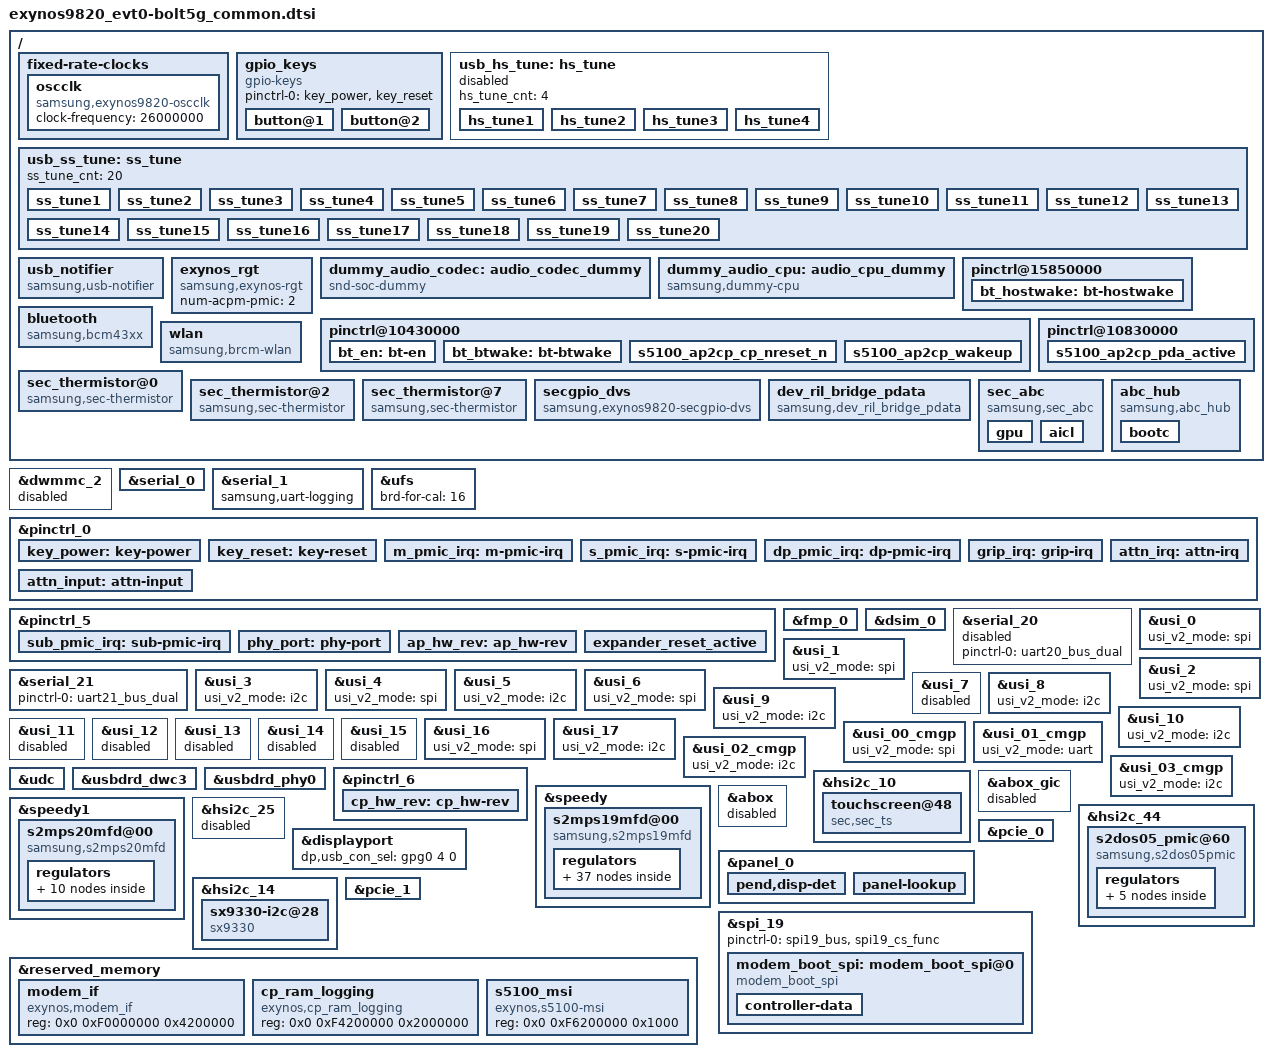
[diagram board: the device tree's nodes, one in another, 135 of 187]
/*
 * SAMSUNG EXYNOS9820 board device tree source
 *
 * Copyright (c) 2018 Samsung Electronics Co., Ltd.
 *		http://www.samsung.com
 *
 * This program is free software; you can redistribute it and/or modify
 * it under the terms of the GNU General Public License version 2 as
 * published by the Free Software Foundation.
*/
#include "modem-s5100-sipc-pdata.dtsi"

/ {

	fragment@model {
		target-path = "/";
		__overlay__ {
			#address-cells = <2>;
			#size-cells = <1>;

			fixed-rate-clocks {
				oscclk {
					compatible = "samsung,exynos9820-oscclk";
					clock-frequency = <26000000>;
				};
			};

			gpio_keys {
				status = "okay";
				compatible = "gpio-keys";
				pinctrl-names = "default";
				pinctrl-0 = <&key_power &key_reset>;
				button@1 {
					label = "gpio-keys: KEY_POWER";
					linux,code = <116>;
					gpios = <&gpa2 4 0xf>;
					gpio-key,wakeup = <1>;
				};
				button@2 {
					label = "gpio-keys: KEY_RESET";
					linux,code = <461>;
					gpios = <&gpa1 1 0xf>;
					gpio-key,wakeup = <1>;
				};
			};

			usb_hs_tune:hs_tune {
				status = "disabled";
				hs_tune_cnt = <4>;
				/* value = <device host> */
				hs_tune1 {
					tune_name = "tx_pre_emp";
					tune_value = <0x3 0x3>;
				};

				hs_tune2 {
					tune_name = "tx_vref";
					tune_value = <0xc 0xc>;
				};

				hs_tune3 {
					tune_name = "rx_sqrx";
					tune_value = <0x5 0x5>;
				};

				hs_tune4 {
					tune_name = "utmi_clk";
					tune_value = <0x1 0x1>;
				};
			};

			usb_ss_tune:ss_tune {
				status = "okay";
				ss_tune_cnt = <20>;
				/* value = <device host> */
				ss_tune1 {
					tune_name = "ssrx_sqhs_th";
					tune_value = <0x4 0x4>;
				};

				ss_tune2 {
					tune_name = "ssrx_lfps_th";
					tune_value = <0x2 0x2>;
				};

				ss_tune3 {
					tune_name = "ssrx_mf_eq_en";
					tune_value = <0x1 0x1>;
				};

				ss_tune4 {
					tune_name = "ssrx_mf_eq_ctrl_ss";
					tune_value = <0x6 0x6>;
				};

				ss_tune5 {
					tune_name = "ssrx_hf_eq_ctrl_ss";
					tune_value = <0xc 0xe>;
				};

				ss_tune6 {
					tune_name = "ssrx_mf_eq_ctrl_ssp";
					tune_value = <0x6 0x6>;
				};

				ss_tune7 {
					tune_name = "ssrx_hf_eq_ctrl_ssp";
					tune_value = <0xe 0xe>;
				};

				ss_tune8 {
					tune_name = "ssrx_dfe1_tap_ctrl";
					tune_value = <0x0 0x2>;
				};

				ss_tune9 {
					tune_name = "ssrx_dfe2_tap_ctrl";
					tune_value = <0x0 0x0>;
				};

				ss_tune10 {
					tune_name = "ssrx_dfe3_tap_ctrl";
					tune_value = <0x0 0x0>;
				};

				ss_tune11 {
					tune_name = "ssrx_dfe4_tap_ctrl";
					tune_value = <0x0 0x0>;
				};

				ss_tune12 {
					tune_name = "ssrx_dfe5_tap_ctrl";
					tune_value = <0x0 0x0>;
				};

				ss_tune13 {
					tune_name = "ssrx_term_cal";
					tune_value = <0xb 0xb>;
				};

				ss_tune14 {
					tune_name = "sstx_amp";
					tune_value = <0xb 0xb>;
				};

				ss_tune15 {
					tune_name = "sstx_deemp";
					tune_value = <0x5 0x5>;
				};

				ss_tune16 {
					tune_name = "sstx_pre_shoot";
					tune_value = <0x3 0x3>;
				};

				ss_tune17 {
					tune_name = "sstx_idrv_up";
					tune_value = <0x7 0x7>;
				};

				ss_tune18 {
					tune_name = "sstx_idrv_dn";
					tune_value = <0x0 0x0>;
				};

				ss_tune19 {
					tune_name = "sstx_up_term";
					tune_value = <0x3 0x3>;
				};

				ss_tune20 {
					tune_name = "sstx_dn_term";
					tune_value = <0x3 0x3>;
				};
			};

			usb_notifier {
				compatible = "samsung,usb-notifier";
				/*
				 * USB_LDOCONTROL_EXYNOS8895	1
				 * USB_LDOCONTROL_EXYNOS9810	2
				 * USB_LDOCONTROL_EXYNOS9820	3
				 */
				usb-ldocontrol = <3>;
				udc = <&udc>;
				disable_host_wakelock;
			};

			exynos_rgt {
				compatible = "samsung,exynos-rgt";
				num-acpm-pmic = <2>;
			};

			dummy_audio_codec: audio_codec_dummy {
				status = "okay";
				compatible = "snd-soc-dummy";
			};

			dummy_audio_cpu: audio_cpu_dummy {
				compatible = "samsung,dummy-cpu";
				status = "okay";
			};

			pinctrl@15850000 {
				bt_hostwake: bt-hostwake {
					samsung,pins = "gpa2-3";
					samsung,pin-function = <0>;
					samsung,pin-pud = <0>;
				};
			};

			pinctrl@10430000 {
				bt_en: bt-en {
					samsung,pins ="gpg0-6";
					samsung,pin-function = <1>;
					samsung,pin-pud = <1>;
					samsung,pin-con-pdn = <3>;
					samsung,pin-pud-pdn = <0>;
				};

				bt_btwake: bt-btwake {
					samsung,pins = "gpg2-0";
					samsung,pin-function = <1>;
					samsung,pin-pud = <0>;
					samsung,pin-con-pdn = <3>;
					samsung,pin-pud-pdn = <0>;
				};

				s5100_ap2cp_cp_nreset_n: s5100_ap2cp_cp_nreset_n {
					samsung,pins = "gpp3-1";
					samsung,pin-con-pdn = <3>;
				};

				s5100_ap2cp_wakeup: s5100_ap2cp_wakeup {
					samsung,pins = "gpg1-7";
					samsung,pin-con-pdn = <3>;
				};
			};

			pinctrl@10830000 {
				s5100_ap2cp_pda_active: s5100_ap2cp_pda_active {
					samsung,pins = "gph1-3";
					samsung,pin-con-pdn = <3>;
				};
			};

			bluetooth {
				compatible = "samsung,bcm43xx";
				gpios = <&gpg0 6 0    /*BT_EN*/
				&gpg2 0 0    /*BT_WAKE*/
				&gpa2 3 0xF    /*BT_HOST_WAKE*/ >;
				pinctrl-names = "default";
				pinctrl-0=<&bt_hostwake &bt_en &bt_btwake>;
				status = "okay";
			};
			
			wlan {
				compatible = "samsung,brcm-wlan";
				gpios = <&gpg0 5 0x1 /* WLAN_EN */
						&gpa0 7 0x1 /* WLAN HOST WAKE GPIO_0 */>;
				pinctrl-names = "default";
				pinctrl-0 = <&cfg_wlanen &wlan_host_wake>;
				status = "okay";
			};

			sec_thermistor@0 {
				compatible = "samsung,sec-thermistor";
				status = "okay";
				thermistor_name = "sec-ap-thermistor";
				id = <0>;

				adc_array = <275 324 380 450 528 619 729 856 1003 1161
					  1345 1545 1766 1980 2222 2457 2685 2901 3102 3279
					  3426 3551 3659>;
				temp_array = <900 850 800 750 700 650 600 550 500 450
					  400 350 300 250 200 150 100 50 0 (-50)
					  (-100) (-150) (-200)>;

				io-channels = <&exynos_adc 0>;
				io-channel-names = "adc-ap-temp";
				io-channel-ranges;
			};

			sec_thermistor@2 {
				compatible = "samsung,sec-thermistor";
				status = "okay";
				thermistor_name = "sec-wf-thermistor";
				id = <1>;

				adc_array = <275 324 380 450 528 619 729 856 1003 1161
					  1345 1545 1766 1980 2222 2457 2685 2901 3102 3279
					  3426 3551 3659>;
				temp_array = <900 850 800 750 700 650 600 550 500 450
					  400 350 300 250 200 150 100 50 0 (-50)
					  (-100) (-150) (-200)>;

				io-channels = <&exynos_adc 2>;
				io-channel-names = "adc-wf-temp";
				io-channel-ranges;
			};

			sec_thermistor@7 {
				compatible = "samsung,sec-thermistor";
				status = "okay";
				thermistor_name = "sec-pa-thermistor";
				id = <2>;

				adc_array = <327 347 367 388 410 433 456 482 507 534
					562 591 621 651 684 717 750 786 821 858
					896 935 975 1016 1057 1100 1143 1187 1231 1277
					1323 1369 1416 1463 1511 1559 1608 1657 1706 1755
					1804 1853 1902 1951 2000 2048 2096 2144 2192 2239
					2285 2332 2378 2421 2467 2510 2553 2596 2637 2678
					2719 2758 2797 2833 2872 2906 2942 2976 3011 3042
					3074 3106 3136 3165 3195 3222 3249 3277 3302 3327
					3352 3375 3397 3420 3441 3461 3482 3502 3520 3538
					3557 3573 3591 3607 3620 3636 3650 3666 3680 3691
					3705 3716 3730 3741 3752 3761 3773 3782 3793 3802
					3812>;

				temp_array =
					<(-200) (-190) (-180) (-170) (-160) (-150) (-140) (-130) (-120) (-110)
					(-100) (-90) (-80) (-70) (-60) (-50) (-40) (-30) (-20) (-10)
					0 10 20 30 40 50 60 70 80 90
					100 110 120 130 140 150 160 170 180 190
					200 210 220 230 240 250 260 270 280 290
					300 310 320 330 340 350 360 370 380 390
					400 410 420 430 440 450 460 470 480 490
					500 510 520 530 540 550 560 570 580 590
					600 610 620 630 640 650 660 670 680 690
					700 710 720 730 740 750 760 770 780 790
					800 810 820 830 840 850 860 870 880 890
					900>;

				io-channels = <&exynos_adc 7>;
				io-channel-names = "adc-pa-temp";
				io-channel-ranges;
			};

			secgpio_dvs {
				compatible = "samsung,exynos9820-secgpio-dvs";
				status = "okay";
			};

			dev_ril_bridge_pdata {
				compatible = "samsung,dev_ril_bridge_pdata";
				status = "okay";
			};

			sec_abc {
				compatible = "samsung,sec_abc";
				status = "okay";

				gpu {
					gpu,label="GPU fault";
					gpu,threshold_count=<20>;
					gpu,threshold_time=<1200>;
				};
				aicl {
					aicl,label="battery aicl";
					aicl,threshold_count=<5>;
					aicl,threshold_time=<300>;
				};
			};

			abc_hub {
				compatible = "samsung,abc_hub";
				status = "okay";

				bootc {
					bootc,time_spec_user = <100000>; /* user binary user build */
					bootc,time_spec_eng = <100000>; /* user binary eng build */
					bootc,time_spec_fac = <100000>; /* factory binary */
				};
			};
		}; /* end of __overlay__ */
	}; /* end of fragment */
}; /* end of root */

&dwmmc_2 {
	status = "disabled";
};


&serial_0 {
	status = "okay";
};

&serial_1 {
	samsung,uart-logging;
	status = "okay";
};

&ufs {
	/* board type for UFS CAL */
	brd-for-cal = /bits/ 8 <16>;  /* (1:SMDK, 16:UNIV) board */
};

&pinctrl_0 {
	key_power: key-power {
		samsung,pins = "gpa2-4";
		samsung,pin-function = <0xf>;
	};

	key_reset: key-reset {
		samsung,pins = "gpa1-1";
		samsung,pin-function = <0xf>;
		samsung,pin-pud = <0>;
		samsung,pin-drv = <0>;
	};

	m_pmic_irq: m-pmic-irq {
		samsung,pins = "gpa0-1";
		samsung,pin-pud = <3>;
		samsung,pin-drv = <3>;
	};

	s_pmic_irq: s-pmic-irq {
		samsung,pins = "gpa2-5";
		samsung,pin-pud = <3>;
		samsung,pin-drv = <3>;
	};

	dp_pmic_irq: dp-pmic-irq {
		samsung,pins = "gpa1-4";
		samsung,pin-function = <0>;
		samsung,pin-pud = <0>;
		samsung,pin-drv = <0>;
	};

	grip_irq: grip-irq {
		samsung,pins = "gpa3-0";
		samsung,pin-function = <0xf>;
		samsung,pin-pud = <0>;
		samsung,pin-drv = <3>;
	};
};

&pinctrl_5 {
	sub_pmic_irq: sub-pmic-irq {
		samsung,pins = "gpg2-1";
		samsung,pin-function = <0>;
		samsung,pin-pud = <0>;
		samsung,pin-drv = <0>;
	};
};

&fmp_0 {
	exynos,block-type = "sda";
	exynos,fips-block_offset = <5>;
};

&dsim_0 {
	lcd_info = <&s6e3ha8>;
	/* reset, power */
	gpios = <&gpa3 4 0x1>;
};

&serial_20 {
	pinctrl-names = "default";
	pinctrl-0 = <&uart20_bus_dual>;
	status = "disabled";
};

&serial_21 {
	pinctrl-names = "default";
	pinctrl-0 = <&uart21_bus_dual>;
	status = "okay";
};

&usi_0 {
	usi_v2_mode = "spi";
	status = "okay";
};

&usi_1 {
	usi_v2_mode = "spi";
	status = "okay";
};

&usi_2 {
	usi_v2_mode = "spi";
	status = "okay";
};

&usi_3 {
	usi_v2_mode = "i2c";
	status = "okay";
};

&usi_4 {
	usi_v2_mode = "spi";
	status = "okay";
};

&usi_5 {
	usi_v2_mode = "i2c";
	status = "okay";
};

&usi_6 {
	usi_v2_mode = "spi";
	status = "okay";
};

&usi_7 {
	status = "disabled";
};

&usi_8 {
	usi_v2_mode = "i2c";
	status = "okay";
};

&usi_9 {
	usi_v2_mode = "i2c";
	status = "okay";
};

&usi_10 {
	usi_v2_mode = "i2c";
	status = "okay";
};

&usi_11 {
	status = "disabled";
};

&usi_12 {
	status = "disabled";
};

&usi_13 {
	status = "disabled";
};

&usi_14 {
	status = "disabled";
};

&usi_15 {
	status = "disabled";
};

&usi_16 {
	usi_v2_mode = "spi";
	status = "okay";
};

&usi_17 {
	usi_v2_mode = "i2c";
	status = "okay";
};

&usi_00_cmgp {
	usi_v2_mode = "spi";
	status = "okay";
};

&usi_01_cmgp {
	usi_v2_mode = "uart";
	status = "okay";
};

&usi_02_cmgp {
	usi_v2_mode = "i2c";
	status = "okay";
};

&usi_03_cmgp {
	usi_v2_mode = "i2c";
	status = "okay";
};

&pinctrl_5 {
	phy_port: phy-port {
		samsung,pins = "gpg0-4";
		samsung,pin-function = <0x0>;
		samsung,pin-pud = <3>;
		samsung,pin-drv = <0>;
	};
};

&udc {
	status = "okay";
};

&usbdrd_dwc3 {
	dr_mode = "otg";
	maximum-speed = "super-speed-plus";
	snps,quirk-frame-length-adjustment = <0x20>;
	snps,u1u2_exitfail_quirk;
	/* ux_exit_in_px should be defined in MK, LT */
	snps,ux_exit_in_px_quirk;
	/* elastic_buf_mode_quirk should be defined in MK */
	snps,elastic_buf_mode_quirk;
	usb3-lpm-capable;
	snps,usb3_lpm_capable;
	snps,has-lpm-erratum;
	snps,lpm-nyet-threshold = <0>;
	/*
	 * dis-u2-freeclk-exists-quirk, dis_u2_susphy_quirk are alternative.
	 * One of them should be selected
	 */
	snps,dis-u2-freeclk-exists-quirk;
	/*snps,dis_u2_susphy_quirk;*/

	usb_audio_offloading = <1>;
	abox = <&abox>; /* Temporary block */
};

&usbdrd_phy0 {
	status = "okay";

	pinctrl-names = "default";
	pinctrl-0 = <&phy_port>; 
 	phy,gpio_phy_port = <&gpg0 4 0x0>;
	reverse_con_dir = <1>;
	hs_tune_param = <&usb_hs_tune>;
	ss_tune_param = <&usb_ss_tune>;
};

&pinctrl_6 {
	/* CP HW revision */
	cp_hw_rev: cp_hw-rev {
		samsung,pins = "gpg3-4", "gpg3-3", "gpg3-2", "gpg3-1";
		samsung,pin-function = <0>;
		samsung,pin-pud = <0>;
		samsung,pin-drv = <0>;
	};
};
&pinctrl_5 {
	/* AP HW revision */
	ap_hw_rev: ap_hw-rev {
		samsung,pins = "gpg1-5", "gpg1-4", "gpg1-3", "gpg1-2";
		samsung,pin-function = <0>;
		samsung,pin-pud = <0>;
		samsung,pin-drv = <0>;
	};
};

&pinctrl_0 {
	attn_irq: attn-irq {
		samsung,pins = "gpa1-0";
		samsung,pin-function = <0xf>;
		samsung,pin-pud = <0>;
		samsung,pin-drv = <0>;
	};

	attn_input: attn-input {
		samsung,pins = "gpa1-0";
		samsung,pin-function = <0>;
		samsung,pin-pud = <1>;
	};
};

&hsi2c_10 {
	#address-cells = <1>;
	#size-cells = <0>;
	status = "okay";
	samsung,reset-before-trans;
	samsung,stop-after-trans;	/* LSI IC ONLY */
	touchscreen@48 {
		compatible = "sec,sec_ts";
		reg = <0x48>;
		pinctrl-names = "on_state", "off_state";
		pinctrl-0 = <&attn_irq>;
		pinctrl-1 = <&attn_input>;
		sec,irq_gpio = <&gpa1 0 0>;
		sec,irq_type = <8200>;
		sec,max_coords = <4096 4096>;
//		sec,area-size = <133 266 341>; /* indicator: 24dp navigator:48dp edge:60px dpi=320 */
		sec,mis_cal_check = <1>;
		sec,regulator_dvdd = "tsp_io";
		sec,regulator_avdd = "tsp_avdd";
		sec,regulator_boot_on;
		sec,tclm_level = <1>;
		support_dex_mode;
		sec,factory_item_version = <2>;
		sec,bringup = <1>;
	};
};

&speedy {
	#address-cells = <1>;
	#size-cells = <0>;
	status = "okay";
	s2mps19mfd@00 {
		compatible = "samsung,s2mps19mfd";
		acpm-ipc-channel = <2>;
		acpm-speedy-channel = <0>;
		i2c-speedy-address;
		s2mps19,wakeup = "enabled";
		s2mps19,irq-gpio = <&gpa0 1 0>;
		reg = <0x00>;
		interrupts = <2 0 0>;
		interrupt-parent = <&gpa0>;
		pinctrl-names = "default";
		pinctrl-0 = <&m_pmic_irq &smpl_warn>;
		gpios = <&gpp3 4 0>;
		smpl_warn_en = <1>; /* 1 : enable , 0 : disable */
		/* range of smpl_warn_vth */
		/* 0x00 : 2.1V, 0x20 : 2.3V, 0x40 : 2.5V, 0x60 : 2.7V 0x80 : 2.9V */
		/* 0xA0 : 3.1V, 0xC0 : 3.3V, 0xE0 : 3.5V */
		smpl_warn_vth = <0xA0>;
		/* LowBat_Hys[4:3] 00(100mV), 01(200mV), 10(300mV), 11(400mV) */
		smpl_warn_hys = <0x00>;
		ocp_warn1_en = <0>; /* 1 : enable, 0 : disable */
		ocp_warn1_cnt = <0>; /* ocp warn reset timing control, 0 : 2 clock, 1 : 32 clock */
		ocp_warn1_dvs_mask = <0>; /* ocp warn mask when dvs, 0 : not masked, 1 : masked  */
		ocp_warn1_lv = <0x0>; /* step : -250mA */
		ocp_warn2_en = <0>; /* 1 : enable, 0 : disable */
		ocp_warn2_cnt = <0>; /* ocp warn reset timing control, 0 : 2 clock, 1 : 32 clock */
		ocp_warn2_dvs_mask = <0>; /* ocp warn mask when dvs, 0 : not masked, 1 : masked  */
		ocp_warn2_lv = <0x0>; /* step : -250mA */
		adc_mode = <1>; /* 0 : disable, 1 : current meter, 2 : power meter */
		adc_sync_mode = <2>; /* 1 : sync mode, 2 : async mode */
		/* RTC: wtsr/smpl */
		wtsr_en = "enabled"; /* enable */
		smpl_en = "enabled"; /* enable */
		wtsr_timer_val = <3>;	/* 1000ms */
		smpl_timer_val = <2>;	/* 300ms */
		sub_smpl_en = "enabled"; /* enable */
		check_jigon = <0>; /* do not check jigon */
		/* RTC: If it's first boot, reset rtc to 1/1/2017 12:00:00(Sun) */
		init_time,sec = <0>;
		init_time,min = <0>;
		init_time,hour = <12>;
		init_time,mday = <1>;
		init_time,mon = <0>;
		init_time,year = <117>;
		init_time,wday = <0>;

		regulators {
			buck1_reg: BUCK1M {
				regulator-name = "m_vdd_buck1";
				regulator-min-microvolt = <450000>;
				regulator-max-microvolt = <1100000>;
				regulator-always-on;
				regulator-ramp-delay = <6000>;
				regulator-initial-mode = <2>;
			};

			buck2_reg: BUCK2M {
				regulator-name = "m_vdd_buck2";
				regulator-min-microvolt = <450000>;
				regulator-max-microvolt = <1300000>;
				regulator-always-on;
				regulator-ramp-delay = <6000>;
				regulator-initial-mode = <2>;
			};

			buck3_reg: BUCK3M {
				regulator-name = "m_vdd_buck3";
				regulator-min-microvolt = <450000>;
				regulator-max-microvolt = <1300000>;
				regulator-always-on;
				regulator-ramp-delay = <6000>;
				regulator-initial-mode = <1>;
			};

			buck4_reg: BUCK4M {
				regulator-name = "m_vdd_buck4";
				regulator-min-microvolt = <450000>;
				regulator-max-microvolt = <1300000>;
				regulator-always-on;
				regulator-ramp-delay = <6000>;
				regulator-initial-mode = <1>;
			};

			buck5_reg: BUCK5M {
				regulator-name = "m_vdd_buck5";
				regulator-min-microvolt = <450000>;
				regulator-max-microvolt = <950000>;
				regulator-always-on;
				regulator-ramp-delay = <6000>;
				regulator-initial-mode = <2>;
			};

			buck6_reg: BUCK6M {
				regulator-name = "m_vdd_buck6";
				regulator-min-microvolt = <450000>;
				regulator-max-microvolt = <1100000>;
				regulator-always-on;
				regulator-ramp-delay = <6000>;
				regulator-initial-mode = <2>;
			};

			buck7_reg: BUCK7M {
				regulator-name = "m_vdd_buck7";
				regulator-min-microvolt = <450000>;
				regulator-max-microvolt = <1300000>;
				regulator-always-on;
				regulator-ramp-delay = <6000>;
				regulator-initial-mode = <2>;
			};

			buck8_reg: BUCK8M {
				regulator-name = "m_vdd_buck8";
				regulator-min-microvolt = <450000>;
				regulator-max-microvolt = <950000>;
				regulator-always-on;
				regulator-ramp-delay = <6000>;
				regulator-initial-mode = <2>;
			};

			buck9_reg: BUCK9M {
				regulator-name = "m_vdd_buck9";
				regulator-min-microvolt = <750000>;
				regulator-max-microvolt = <1150000>;
				regulator-always-on;
				regulator-ramp-delay = <6000>;
				regulator-initial-mode = <3>;
			};

			buck10_reg: BUCK10M {
				regulator-name = "m_vdd_buck10";
				regulator-min-microvolt = <900000>;
				regulator-max-microvolt = <1300000>;
				regulator-always-on;
				regulator-ramp-delay = <6000>;
				regulator-initial-mode = <3>;
			};

			buck11_reg: BUCK11M {
				regulator-name = "m_vdd_buck11";
				regulator-min-microvolt = <1100000>;
				regulator-max-microvolt = <1500000>;
				regulator-always-on;
				regulator-ramp-delay = <6000>;
				regulator-initial-mode = <3>;
			};

			buck12_reg: BUCK12M {
				regulator-name = "m_vdd_buck12";
				regulator-min-microvolt = <1700000>;
				regulator-max-microvolt = <2150000>;
				regulator-always-on;
				regulator-ramp-delay = <6000>;
				regulator-initial-mode = <3>;
			};

			ldo1_reg: LDO1M {
				regulator-name = "m_vdd_ldo1";
				regulator-min-microvolt = <700000>;
				regulator-max-microvolt = <950000>;
				regulator-always-on;
				regulator-ramp-delay = <12000>;
				regulator-initial-mode = <3>;
			};

			ldo3_reg: LDO3M {
				regulator-name = "m_vdd_ldo3";
				regulator-min-microvolt = <700000>;
				regulator-max-microvolt = <1100000>;
				regulator-always-on;
				regulator-ramp-delay = <12000>;
				regulator-initial-mode = <1>;
			};

			ldo4_reg: LDO4M {
				regulator-name = "m_vdd_ldo4";
				regulator-min-microvolt = <1600000>;
				regulator-max-microvolt = <1950000>;
				regulator-always-on;
				regulator-ramp-delay = <12000>;
				regulator-initial-mode = <1>;
			};

			ldo5_reg: LDO5M {
				regulator-name = "m_vdd_ldo5";
				regulator-min-microvolt = <450000>;
				regulator-max-microvolt = <1100000>;
				regulator-always-on;
				regulator-ramp-delay = <12000>;
				regulator-initial-mode = <1>;
			};

			ldo6_reg: LDO6M {
				regulator-name = "m_vdd_ldo6";
				regulator-min-microvolt = <450000>;
				regulator-max-microvolt = <950000>;
				regulator-always-on;
				regulator-ramp-delay = <12000>;
				regulator-initial-mode = <1>;
			};

			ldo7_reg: LDO7M {
				regulator-name = "m_vdd_ldo7";
				regulator-min-microvolt = <450000>;
				regulator-max-microvolt = <1100000>;
				regulator-always-on;
				regulator-ramp-delay = <12000>;
				regulator-initial-mode = <1>;
			};

			ldo8_reg: LDO8M {
				regulator-name = "m_vdd_ldo8";
				regulator-min-microvolt = <450000>;
				regulator-max-microvolt = <1300000>;
				regulator-always-on;
				regulator-ramp-delay = <12000>;
				regulator-initial-mode = <1>;
			};

			ldo9_reg: LDO9M {
				regulator-name = "m_vdd_ldo9";
				regulator-min-microvolt = <700000>;
				regulator-max-microvolt = <1300000>;
				regulator-always-on;
				regulator-ramp-delay = <12000>;
				regulator-initial-mode = <1>;
			};

			ldo10_reg: LDO10M {
				regulator-name = "m_vdd_ldo10";
				regulator-min-microvolt = <700000>;
				regulator-max-microvolt = <1100000>;
				regulator-boot-on;
				regulator-ramp-delay = <12000>;
				regulator-initial-mode = <3>;
			};

			ldo11_reg: LDO11M {
				regulator-name = "m_vdd_ldo11";
				regulator-min-microvolt = <1600000>;
				regulator-max-microvolt = <1950000>;
				regulator-boot-on;
				regulator-ramp-delay = <12000>;
				regulator-initial-mode = <3>;
			};

			ldo12_reg: LDO12M {
				regulator-name = "m_vdd_ldo12";
				regulator-min-microvolt = <1700000>;
				regulator-max-microvolt = <3350000>;
				regulator-boot-on;
				regulator-ramp-delay = <12000>;
				regulator-initial-mode = <3>;
			};

			ldo16_reg: LDO16M {
				regulator-name = "m_vdd_ldo16";
				regulator-min-microvolt = <2500000>;
				regulator-max-microvolt = <3300000>;
				regulator-always-on;
				regulator-ramp-delay = <12000>;
				regulator-initial-mode = <3>;
			};

			ldo17_reg: LDO17M {
				regulator-name = "m_vdd_ldo17";
				regulator-min-microvolt = <1600000>;
				regulator-max-microvolt = <2200000>;
				regulator-always-on;
				regulator-ramp-delay = <12000>;
				regulator-initial-mode = <3>;
			};

			ldo18_reg: LDO18M {
				regulator-name = "m_vdd_ldo18";
				regulator-min-microvolt = <700000>;
				regulator-max-microvolt = <1200000>;
				regulator-always-on;
				regulator-ramp-delay = <12000>;
				regulator-initial-mode = <3>;
			};

			ldo19_reg: LDO19M {
				regulator-name = "tsp_io";
				regulator-min-microvolt = <1800000>;
				regulator-max-microvolt = <1800000>;
				regulator-always-on;
				regulator-ramp-delay = <12000>;
				regulator-initial-mode = <2>;
			};

			ldo20_reg: LDO20M {
				regulator-name = "m_vdd_ldo20";
				regulator-min-microvolt = <2500000>;
				regulator-max-microvolt = <3300000>;
				regulator-always-on;
				regulator-ramp-delay = <12000>;
				regulator-initial-mode = <3>;
			};

			ldo21_reg: LDO21M {
				regulator-name = "vdd_mcu_1p8";
				regulator-min-microvolt = <1800000>;
				regulator-max-microvolt = <1800000>;
				regulator-always-on;
				regulator-ramp-delay = <12000>;
				regulator-initial-mode = <3>;
			};

			ldo22_reg: LDO22M {
				regulator-name = "VDD_NFC_1P8";
				regulator-min-microvolt = <1800000>;
				regulator-max-microvolt = <1800000>;
				regulator-ramp-delay = <12000>;
				regulator-initial-mode = <2>;
			};

			ldo23_reg: LDO23M {
				regulator-name = "VDDD_1.2V_FRONTSUB";
				regulator-min-microvolt = <1200000>;
				regulator-max-microvolt = <1200000>;
				regulator-ramp-delay = <12000>;
				regulator-initial-mode = <3>;
			};

			ldo24_reg: LDO24M {
				regulator-name = "VDDA_2.8V_FRONTSUB";
				regulator-min-microvolt = <2800000>;
				regulator-max-microvolt = <2800000>;
				regulator-ramp-delay = <12000>;
				regulator-initial-mode = <3>;
			};

			ldo25_reg: LDO25M {
				regulator-name = "VDDIO_1.8V_FRONTSUB";
				regulator-min-microvolt = <1800000>;
				regulator-max-microvolt = <1800000>;
				regulator-ramp-delay = <12000>;
				regulator-initial-mode = <3>;
			};

			ldo26_reg: LDO26M {
				regulator-name = "m_vdd_ldo26";
				regulator-min-microvolt = <1600000>;
				regulator-max-microvolt = <2200000>;
				regulator-always-on;
				regulator-ramp-delay = <12000>;
				regulator-initial-mode = <3>;
			};

			ldo27_reg: LDO27M {
				regulator-name = "tsp_avdd";
				regulator-min-microvolt = <3000000>;
				regulator-max-microvolt = <3000000>;
				regulator-boot-on;
				regulator-ramp-delay = <12000>;
				regulator-initial-mode = <3>;
			};

			ldo28_reg: LDO28M {
				regulator-name = "m_vdd_ldo28";
				regulator-min-microvolt = <1600000>;
				regulator-max-microvolt = <2200000>;
				regulator-always-on;
				regulator-ramp-delay = <12000>;
				regulator-initial-mode = <3>;
			};

			ldo29_reg: LDO29M {
				regulator-name = "m_vdd_ldo29";
				regulator-min-microvolt = <2500000>;
				regulator-max-microvolt = <3300000>;
				regulator-always-on;
				regulator-ramp-delay = <12000>;
				regulator-initial-mode = <3>;
			};
		};
	};
};

&speedy1 {
	#address-cells = <1>;
	#size-cells = <0>;
	status = "okay";
	s2mps20mfd@00 {
		compatible = "samsung,s2mps20mfd";
		acpm-ipc-channel = <2>;
		acpm-speedy-channel = <1>;
		i2c-speedy-address;
		s2mps20,wakeup = "enabled";
		s2mps20,irq-gpio = <&gpa2 5 0>;
		reg = <0x00>;
		interrupts = <1 0 0>;
		interrupt-parent = <&gpa2>;
		pinctrl-names = "default";
		pinctrl-0 = <&s_pmic_irq>;
		adc_mode = <1>; /* 0 : disable, 1 : current meter, 2 : power meter */
		adc_sync_mode = <2>; /* 1 : sync mode, 2 : async mode */
		ocp_warn3_en = <0>; /* 1 : enable, 0 : disable */
		ocp_warn3_cnt = <0>; /* ocp warn reset timing control, 0 : 2 clock, 1 : 32 clock */
		ocp_warn3_dvs_mask = <0>; /* ocp warn mask when dvs, 0 : not masked, 1 : masked  */
		ocp_warn3_lv = <0x0>; /* step : -250mA */

		regulators {
			s_buck1_reg: BUCK1S {
				regulator-name = "s_vdd_buck1";
				regulator-min-microvolt = <450000>;
				regulator-max-microvolt = <950000>;
				regulator-always-on;
				regulator-ramp-delay = <6000>;
				regulator-initial-mode = <2>;
			};

			s_buck2_reg: BUCK2S {
				regulator-name = "s_vdd_buck2";
				regulator-min-microvolt = <900000>;
				regulator-max-microvolt = <1300000>;
				regulator-always-on;
				regulator-ramp-delay = <6000>;
				regulator-initial-mode = <3>;
			};

			s_ldo1_reg: LDO1S {
				regulator-name = "s_vdd_ldo1";
				regulator-min-microvolt = <450000>;
				regulator-max-microvolt = <950000>;
				regulator-always-on;
				regulator-ramp-delay = <12000>;
				regulator-initial-mode = <1>;
			};

			s_ldo2_reg: LDO2S {
				regulator-name = "s_vdd_ldo2";
				regulator-min-microvolt = <1600000>;
				regulator-max-microvolt = <1950000>;
				regulator-always-on;
				regulator-ramp-delay = <12000>;
				regulator-initial-mode = <3>;
			};

			s_ldo7_reg: LDO7S {
				regulator-name = "s_vdd_ldo7";
				regulator-min-microvolt = <1600000>;
				regulator-max-microvolt = <1950000>;
				regulator-always-on;
				regulator-ramp-delay = <12000>;
				regulator-initial-mode = <3>;
			};

			s_ldo8_reg: LDO8S {
				regulator-name = "s_vdd_ldo8";
				regulator-min-microvolt = <700000>;
				regulator-max-microvolt = <1100000>;
				regulator-always-on;
				regulator-ramp-delay = <12000>;
				regulator-initial-mode = <3>;
			};

			s_ldo9_reg: LDO9S {
				regulator-name = "s_vdd_ldo9";
				regulator-min-microvolt = <700000>;
				regulator-max-microvolt = <1100000>;
				regulator-always-on;
				regulator-ramp-delay = <12000>;
				regulator-initial-mode = <3>;
			};

			s_ldo10_reg: LDO10S {
				regulator-name = "s_vdd_ldo10";
				regulator-min-microvolt = <1600000>;
				regulator-max-microvolt = <1950000>;
				regulator-always-on;
				regulator-ramp-delay = <12000>;
				regulator-initial-mode = <3>;
			};

			s_ldo11_reg: LDO11S {
				regulator-name = "s_vdd_ldo11";
				regulator-min-microvolt = <1600000>;
				regulator-max-microvolt = <1950000>;
				regulator-always-on;
				regulator-ramp-delay = <12000>;
				regulator-initial-mode = <3>;
			};

			s_ldo12_reg: LDO12S {
				regulator-name = "s_vdd_ldo12";
				regulator-min-microvolt = <1700000>;
				regulator-max-microvolt = <3350000>;
				regulator-always-on;
				regulator-ramp-delay = <12000>;
				regulator-initial-mode = <3>;
			};
		};
	};
};

&abox_gic {
	status = "disabled";
};

&abox {
	status = "disabled";
};

&hsi2c_44 {
	#address-cells = <1>;
	#size-cells = <0>;
	status = "okay";
	s2dos05_pmic@60 {
		compatible = "samsung,s2dos05pmic";
		reg = <0x60>;
		s2dos05,wakeup;
		pinctrl-names = "default";
		pinctrl-0 = <&dp_pmic_irq>;
		s2dos05,s2dos05_int = <&gpa1 4 0>;
		adc_mode = <1>; /* 0 : disable, 1 : current meter, 2 : power meter */
		adc_sync_mode = <2>; /* 1 : sync mode, 2 : async mode */
		regulators {
			dp_buck: s2dos05-buck1 {
				regulator-name = "vdd1";
				regulator-min-microvolt = <1500000>;
				regulator-max-microvolt = <1600000>;
				regulator-boot-on;
			};
			dp_ldo1: s2dos05-ldo1 {
				regulator-name = "vdd2";
				regulator-min-microvolt = <1800000>;
				regulator-max-microvolt = <1800000>;
				regulator-boot-on;
			};
			dp_ldo2: s2dos05-ldo2 {
				regulator-name = "vdd3";
				regulator-min-microvolt = <1500000>;
				regulator-max-microvolt = <2000000>;
				regulator-always-on;
				regulator-boot-on;
			};
			dp_ldo3: s2dos05-ldo3{
				regulator-name = "vdd4";
				regulator-min-microvolt = <2700000>;
				regulator-max-microvolt = <3775000>;
				regulator-always-on;
				regulator-boot-on;
			};
			dp_ldo4: s2dos05-ldo4{
				regulator-name = "vdd5";
				regulator-min-microvolt = <3000000>;
				regulator-max-microvolt = <3000000>;
				regulator-boot-on;
			};
		};
	};
};

/***** reference symbol node *****/
&pinctrl_5 {
expander_reset_active: expander_reset_active {
	       samsung,pins = "gpg4-0";
	       samsung,pin-function = <1>;
	       samsung,pin-pud = <0>;
	       samsung,pin-val = <1>;
       };
};

&hsi2c_25 {
	#address-cells = <1>;
	#size-cells = <0>;
	status = "disabled";
};

&pcie_0 {
	pinctrl-names = "default","idle";
	pinctrl-0 = <&pcie0_clkreq &pcie0_perst &pcie_wake &cfg_wlanen &wlan_host_wake>;
	pinctrl-1 = <&pcie0_perst &pcie_wake &cfg_wlanen &wlan_host_wake>;
	status = "okay";
	use-sysmmu = "true";
	use-cache-coherency = "true";
	use-msi = "false";
	ep-device-type = <EP_BCM_WIFI>;
};

&displayport {
	status = "okay";
	dp,usb_con_sel = <&gpg0 4 0>;

	pinctrl-names = "default";
};

&panel_0 {

    status = "okay";

	ddi_info = <&s6e3ha8>; 
	gpio,lcd-reset = <&gpa3 4 0x1>;
	gpio,disp-det = <&gpg2 2 0x0>;

	regulator,3p0 = "vdd5";
	regulator,1p8 = "vdd2";
	regulator,1p6 = "vdd1";

	#address-cells = <2>;
	#size-cells = <1>;
	ranges;

	pend,disp-det {
		reg = <0x0 0x10430A08 0x4>;
		pend-bit = <0x2>;
	};

	panel-lookup {
		panel-name = "s6e3ha8_crown_a3_s0_preliminary";
		panel-ddi-info = <&s6e3ha8>;
		panel-lut = <
			0xD11443 0xFFFFFF 0x0 0x0  /* CROWN TEMPORARY PANEL */
			0x911443 0xFFFFFF 0x0 0x0  /* CROWN TEMPORARY PANEL */
			0x910046 0xFFFFFF 0x0 0x0  /* CROWN TEMPORARY PANEL */

			/* default panel */
			0x000000 0x000000 0x0 0x0  /* not found */
		>;
	};
};

&hsi2c_14 {
	gpios = <&gpp2 4 0 &gpp2 5 0>;
	clock-frequency = <400000>;
	status = "okay";

	#address-cells = <1>;
	#size-cells = <0>;

	sx9330-i2c@28 {
		compatible = "sx9330";
		reg = <0x28>;
		status = "okay";
		pinctrl-names = "default";
		pinctrl-0 = <&grip_irq>;
		interrupt-parent = <&gpa3>;
		interrupts = <0 0 0>;

		sx9330,nirq-gpio = <&gpa3 0 0>;
	};
};

&spi_19 {
	#address-cells = <1>;
	#size-cells = <0>;
	status = "okay";
	pinctrl-names = "default";
	pinctrl-0 = <&spi19_bus &spi19_cs_func>;
	modem_boot_spi: modem_boot_spi@0 {
		compatible = "modem_boot_spi";
		reg = <0x0>;
		spi-max-frequency = <4000000>;
		controller-data {
			samsung,spi-feedback-delay = <0>;
			samsung,spi-chip-select-mode = <1>;
		};
	};
}; /* end of spi_19 */

&pcie_1 {
	status = "okay";
	use-sysmmu = "false";
	use-cache-coherency = "true";
	use-msi = "true";
	use-sicd = "true";
	ep-device-type = <EP_SAMSUNG_MODEM>;
	phy-power-off = "false";  /* 'true' is only for Exynos9820 SMDK board */
};

&reserved_memory {
	#address-cells = <2>;
	#size-cells = <1>;

	modem_if {
		/* 66MB: VSS 2MB, SHM MEM 64MB */
		compatible = "exynos,modem_if";
		reg = <0x0 0xF0000000 0x4200000>;
	};

	cp_ram_logging {
		/* 32MB */
		compatible = "exynos,cp_ram_logging";
		reg = <0x0 0xF4200000 0x2000000>;
	};

	s5100_msi {
		/* 4KB */
		compatible = "exynos,s5100-msi";
		reg = <0x0 0xF6200000 0x1000>;
	};
};

&speedy {
	s2mps19mfd@00 {
		smpl_warn_dev2= <0>;
	};
};
